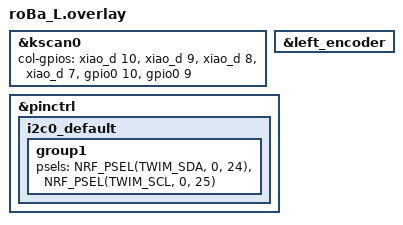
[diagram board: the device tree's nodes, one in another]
#include "roBa.dtsi"

&kscan0 {
        col-gpios
            = <&xiao_d 10 GPIO_ACTIVE_HIGH>
            , <&xiao_d 9 GPIO_ACTIVE_HIGH> 
            , <&xiao_d 8 GPIO_ACTIVE_HIGH> 
            , <&xiao_d 7 GPIO_ACTIVE_HIGH> 
            , <&gpio0 10 GPIO_ACTIVE_HIGH>
            , <&gpio0 9 GPIO_ACTIVE_HIGH>
            ;
};

&left_encoder {
    status = "okay";
};

&pinctrl {
    #binding-cells = <1>;
    
    i2c0_default: i2c0_default {
        group1 {
            psels = <NRF_PSEL(TWIM_SDA, 0, 24)>,
                    <NRF_PSEL(TWIM_SCL, 0, 25)>;
        };
    };
};
